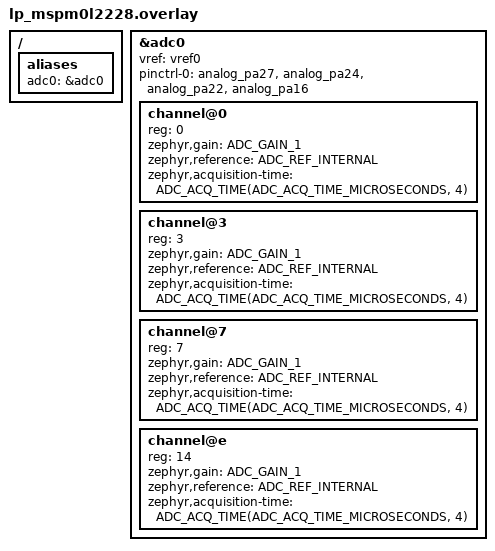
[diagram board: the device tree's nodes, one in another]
/*
 * SPDX-FileCopyrightText: 2026 Texas Instruments Incorporated
 *
 * SPDX-License-Identifier: Apache-2.0
 */

#include <dt-bindings/adc/adc.h>

/ {
	aliases {
		adc0 = &adc0;
	};
};

&adc0 {
	vref = <&vref0>;
	pinctrl-0 = <
		&analog_pa27 /* ADC0.0 */
		&analog_pa24 /* ADC0.3 */
		&analog_pa22 /* ADC0.7 */
		&analog_pa16 /* ADC0.14 */
	>;
	pinctrl-names = "default";
	status = "okay";
	#address-cells = <1>;
	#size-cells = <0>;

	channel@0 {
		reg = <0>;
		zephyr,gain = "ADC_GAIN_1";
		zephyr,reference = "ADC_REF_INTERNAL";
		zephyr,acquisition-time = <ADC_ACQ_TIME(ADC_ACQ_TIME_MICROSECONDS, 4)>;
	};

	channel@3 {
		reg = <3>;
		zephyr,gain = "ADC_GAIN_1";
		zephyr,reference = "ADC_REF_INTERNAL";
		zephyr,acquisition-time = <ADC_ACQ_TIME(ADC_ACQ_TIME_MICROSECONDS, 4)>;
	};

	channel@7 {
		reg = <7>;
		zephyr,gain = "ADC_GAIN_1";
		zephyr,reference = "ADC_REF_INTERNAL";
		zephyr,acquisition-time = <ADC_ACQ_TIME(ADC_ACQ_TIME_MICROSECONDS, 4)>;
	};

	channel@e {
		reg = <14>;
		zephyr,gain = "ADC_GAIN_1";
		zephyr,reference = "ADC_REF_INTERNAL";
		zephyr,acquisition-time = <ADC_ACQ_TIME(ADC_ACQ_TIME_MICROSECONDS, 4)>;
	};
};
